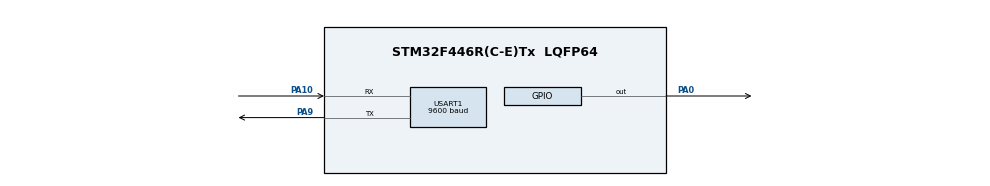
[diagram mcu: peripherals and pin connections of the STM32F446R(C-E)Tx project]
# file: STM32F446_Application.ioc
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Mcu.Family=STM32F4
Mcu.Name=STM32F446R(C-E)Tx
Mcu.Package=LQFP64
NVIC.PriorityGroup=NVIC_PRIORITYGROUP_4
PA0-WKUP.Signal=GPIO_Output
PA10.Mode=Asynchronous
PA10.Signal=USART1_RX
PA9.Mode=Asynchronous
PA9.Signal=USART1_TX
ProjectManager.HeapSize=0x200
ProjectManager.StackSize=0x400
ProjectManager.TargetToolchain=CMake
RCC.CortexFreq_Value=16000000
RCC.USBFreq_Value=96000000
RCC.VCOOutputFreq_Value=192000000
USART1.BaudRate=9600
USART1.VirtualMode=VM_ASYNC
board=custom

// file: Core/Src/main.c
/* USER CODE BEGIN Header */
/**
  ******************************************************************************
  * @file           : main.c
  * @brief          : Main program body
  ******************************************************************************
  * @attention
  *
  * Copyright (c) 2026 STMicroelectronics.
  * All rights reserved.
  *
  * This software is licensed under terms that can be found in the LICENSE file
  * in the root directory of this software component.
  * If no LICENSE file comes with this software, it is provided AS-IS.
  *
  ******************************************************************************
  */
/* USER CODE END Header */
#include "main.h"

/* USER CODE BEGIN Includes */
#include "boot_shared.h"
#include <string.h>
/* USER CODE END Includes */

UART_HandleTypeDef huart1;

void SystemClock_Config(void);
static void MX_GPIO_Init(void);
static void MX_USART1_UART_Init(void);

/* USER CODE BEGIN 0 */

static void uart_print(const char *s)
{
    HAL_UART_Transmit(&huart1, (uint8_t *)s, (uint16_t)strlen(s), 500);
}

/* Watch the bytes coming from the HC-05 for the text "OTA". On a match, hand over to
   the bootloader, which then waits for tools/ota_upload.py to send the new image. */
static void ota_command_poll(void)
{
    static const char trigger[] = "OTA";
    static uint32_t matched = 0;

    if (!__HAL_UART_GET_FLAG(&huart1, UART_FLAG_RXNE))
        return;

    char c = (char)(huart1.Instance->DR & 0xFFu);   /* reading DR also clears an overrun */

    if (c == trigger[matched])
        matched++;
    else
        matched = (c == trigger[0]) ? 1 : 0;

    if (matched == sizeof(trigger) - 1)
    {
        uart_print("Rebooting into bootloader for OTA\r\n");
        boot_request_ota_and_reset();
    }
}

/* USER CODE END 0 */

int main(void)
{

  /* MCU Configuration--------------------------------------------------------*/

  /* Reset of all peripherals, Initializes the Flash interface and the Systick. */
  HAL_Init();

  /* Configure the system clock */
  SystemClock_Config();

  /* Initialize all configured peripherals */
  MX_GPIO_Init();
  MX_USART1_UART_Init();
  /* USER CODE BEGIN 2 */
  uart_print("App running\r\n");
  uint32_t last_blink = HAL_GetTick();
  /* USER CODE END 2 */

  /* Infinite loop */
  while (1)
  {

    /* USER CODE BEGIN 3 */
    /* Heartbeat: if this blinks, SysTick reaches the app (vector table moved correctly) */
    if (HAL_GetTick() - last_blink >= 500)
    {
        last_blink = HAL_GetTick();
        HAL_GPIO_TogglePin(GPIOA, GPIO_PIN_0);
    }

    ota_command_poll();
  }
  /* USER CODE END 3 */
}

void SystemClock_Config(void)
{
  RCC_OscInitTypeDef RCC_OscInitStruct = {0};
  RCC_ClkInitTypeDef RCC_ClkInitStruct = {0};

  /** Configure the main internal regulator output voltage
  */
  __HAL_RCC_PWR_CLK_ENABLE();
  __HAL_PWR_VOLTAGESCALING_CONFIG(PWR_REGULATOR_VOLTAGE_SCALE3);

  /** Initializes the RCC Oscillators according to the specified parameters
  * in the RCC_OscInitTypeDef structure.
  */
  RCC_OscInitStruct.OscillatorType = RCC_OSCILLATORTYPE_HSI;
  RCC_OscInitStruct.HSIState = RCC_HSI_ON;
  RCC_OscInitStruct.HSICalibrationValue = RCC_HSICALIBRATION_DEFAULT;
  RCC_OscInitStruct.PLL.PLLState = RCC_PLL_NONE;
  if (HAL_RCC_OscConfig(&RCC_OscInitStruct) != HAL_OK)
  {
    Error_Handler();
  }

  /** Initializes the CPU, AHB and APB buses clocks
  */
  RCC_ClkInitStruct.ClockType = RCC_CLOCKTYPE_HCLK|RCC_CLOCKTYPE_SYSCLK
                              |RCC_CLOCKTYPE_PCLK1|RCC_CLOCKTYPE_PCLK2;
  RCC_ClkInitStruct.SYSCLKSource = RCC_SYSCLKSOURCE_HSI;
  RCC_ClkInitStruct.AHBCLKDivider = RCC_SYSCLK_DIV1;
  RCC_ClkInitStruct.APB1CLKDivider = RCC_HCLK_DIV1;
  RCC_ClkInitStruct.APB2CLKDivider = RCC_HCLK_DIV1;

  if (HAL_RCC_ClockConfig(&RCC_ClkInitStruct, FLASH_LATENCY_0) != HAL_OK)
  {
    Error_Handler();
  }
}

static void MX_USART1_UART_Init(void)
{

  huart1.Instance = USART1;
  huart1.Init.BaudRate = 9600;
  huart1.Init.WordLength = UART_WORDLENGTH_8B;
  huart1.Init.StopBits = UART_STOPBITS_1;
  huart1.Init.Parity = UART_PARITY_NONE;
  huart1.Init.Mode = UART_MODE_TX_RX;
  huart1.Init.HwFlowCtl = UART_HWCONTROL_NONE;
  huart1.Init.OverSampling = UART_OVERSAMPLING_16;
  if (HAL_UART_Init(&huart1) != HAL_OK)
  {
    Error_Handler();
  }

}

static void MX_GPIO_Init(void)
{
  GPIO_InitTypeDef GPIO_InitStruct = {0};

  /* GPIO Ports Clock Enable */
  __HAL_RCC_GPIOA_CLK_ENABLE();

  /*Configure GPIO pin Output Level */
  HAL_GPIO_WritePin(GPIOA, GPIO_PIN_0, GPIO_PIN_RESET);

  /*Configure GPIO pin : PA0 */
  GPIO_InitStruct.Pin = GPIO_PIN_0;
  GPIO_InitStruct.Mode = GPIO_MODE_OUTPUT_PP;
  GPIO_InitStruct.Pull = GPIO_NOPULL;
  GPIO_InitStruct.Speed = GPIO_SPEED_FREQ_LOW;
  HAL_GPIO_Init(GPIOA, &GPIO_InitStruct);

}

void Error_Handler(void)
{
  __disable_irq();
  while (1)
  {
  }
}
